# N32L406 register map
Vendor: Nsing Technologies Pte. Ltd.; File version: 1.0
Registers are 32-bit, read-write, reset 0x0 unless marked. A register's access mark holds for its fields unless they carry their own. Offsets are from the block's base; [hi:lo] are bit positions; {n}, {i} and the like mark numbered series; 'fields as' and 'values as' point back to an identical list.

## CRC — cyclic redundancy check
Base 0x40023000
0x00 CRC32DAT reset 0xFFFFFFFF
0x04 CRC32IDAT
  [7:0] CRC32IDAT
0x08 CRC32CTRL
  [0] RESET
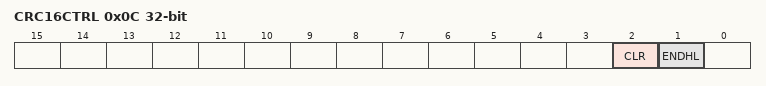
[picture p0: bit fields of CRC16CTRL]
0x0C CRC16CTRL
  [2] CLR, [1] ENDHL
0x10 CRC16DAT
  [7:0] CRC16DAT
0x14 CRC16D
  [15:0] CRC16D
0x18 LRC
  [7:0] LRCDAT

## DAC — digital to analog converter
Base 0x40007400
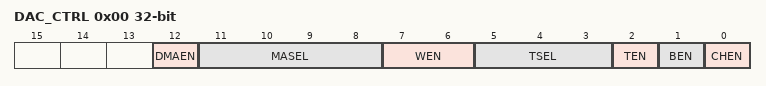
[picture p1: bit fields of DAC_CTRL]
0x00 DAC_CTRL
  [12] DMAEN, [11:8] MASEL, [7:6] WEN, [5:3] TSEL, [2] TEN, [1] BEN, [0] CHEN
0x04 DAC_SOTTR write
  [0] TR1EN
0x08 DAC_DR12CH
  [11:0] DACCHD
0x0C DAC_DL12CH
  [15:4] DACCHD
0x10 DAC_DR8CH
  [7:0] DACCHD
0x2C DAC_DATO
  [11:0] DACCHDO

## DBG — debug support for MCU
Base 0xE0042000
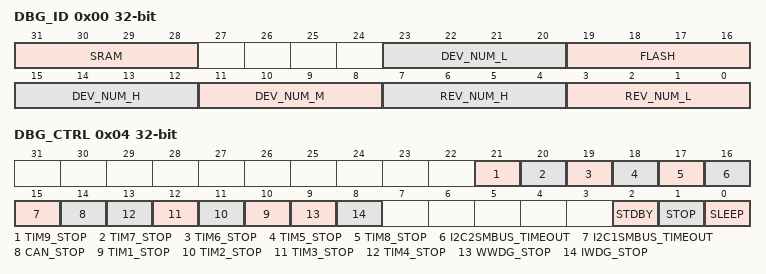
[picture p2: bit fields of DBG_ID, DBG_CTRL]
0x00 DBG_ID
  [31:28] SRAM, [23:20] DEV_NUM_L, [19:16] FLASH, [15:12] DEV_NUM_H, [11:8] DEV_NUM_M, [7:4] REV_NUM_H, [3:0] REV_NUM_L
0x04 DBG_CTRL
  [21] TIM9_STOP, [20] TIM7_STOP, [19] TIM6_STOP, [18] TIM5_STOP, [17] TIM8_STOP, [16] I2C2SMBUS_TIMEOUT, [15] I2C1SMBUS_TIMEOUT, [14] CAN_STOP, [n+9] TIM{n}_STOP (n=1..4), [9] WWDG_STOP, [8] IWDG_STOP, [2] STDBY, [1] STOP, [0] SLEEP

## DMA — Direct memory access controller
Base 0x40020000
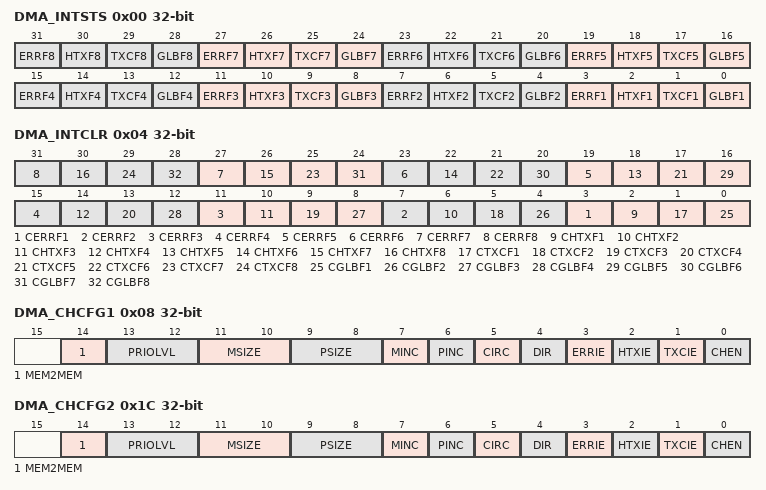
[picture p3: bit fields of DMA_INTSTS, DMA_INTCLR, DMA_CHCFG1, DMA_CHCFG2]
0x00 DMA_INTSTS
  [4n-1] ERRF{n} (n=1..8), [4n-2] HTXF{n} (n=1..8), [4n-3] TXCF{n} (n=1..8), [4n-4] GLBF{n} (n=1..8)
0x04 DMA_INTCLR
  [4n-1] CERRF{n} (n=1..8), [4n-2] CHTXF{n} (n=1..8), [4n-3] CTXCF{n} (n=1..8), [4n-4] CGLBF{n} (n=1..8)
0x08 DMA_CHCFG1
  [14] MEM2MEM, [13:12] PRIOLVL, [11:10] MSIZE, [9:8] PSIZE, [7] MINC, [6] PINC, [5] CIRC, [4] DIR, [3] ERRIE, [2] HTXIE, [1] TXCIE, [0] CHEN
0x0C DMA_TXNUM1
  [15:0] NDTX
0x10 DMA_PADDR1
  [31:0] ADDR
{0x0+0x14*i} DMA_MADDR{i} (i=1..8)
  [31:0] ADDR
{0x4+0x14*i} DMA_CHSEL{i} (i=1..8)
  [5:0] CH_SEL
0x1C DMA_CHCFG2
  fields as DMA_CHCFG1
0x20 DMA_TXNUM2
  [15:0] NDTX
0x24 DMA_PADDR2
  [31:0] ADDR
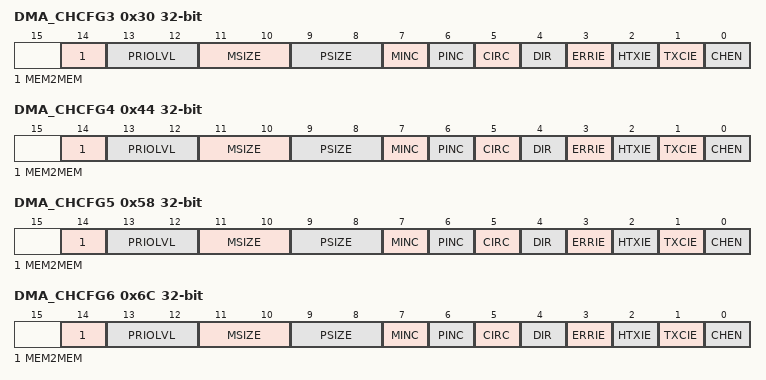
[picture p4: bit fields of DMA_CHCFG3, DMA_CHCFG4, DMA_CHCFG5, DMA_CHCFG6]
0x30 DMA_CHCFG3
  fields as DMA_CHCFG1
0x34 DMA_TXNUM3
  [15:0] NDTX
0x38 DMA_PADDR3
  [31:0] ADDR
0x44 DMA_CHCFG4
  fields as DMA_CHCFG1
0x48 DMA_TXNUM4
  [15:0] NDTX
0x4C DMA_PADDR4
  [31:0] ADDR
0x58 DMA_CHCFG5
  fields as DMA_CHCFG1
0x5C DMA_TXNUM5
  [15:0] NDTX
0x60 DMA_PADDR5
  [31:0] ADDR
0x6C DMA_CHCFG6
  fields as DMA_CHCFG1
0x70 DMA_TXNUM6
  [15:0] NDTX
0x74 DMA_PADDR6
  [31:0] ADDR
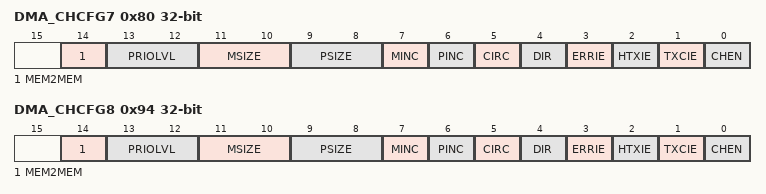
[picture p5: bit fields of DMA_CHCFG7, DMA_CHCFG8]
0x80 DMA_CHCFG7
  fields as DMA_CHCFG1
0x84 DMA_TXNUM7
  [15:0] NDTX
0x88 DMA_PADDR7
  [31:0] ADDR
0x94 DMA_CHCFG8
  fields as DMA_CHCFG1
0x98 DMA_TXNUM8
  [15:0] NDTX
0x9C DMA_PADDR8
  [31:0] ADDR

## EXTI — external interrupt/event controller
Base 0x40010400
0x00 EXTI_IMASK
  [27:0] IMASK
0x04 EXTI_EMASK
  [27:0] EMASK
0x08 EXTI_RT_CFG
  [27:0] RT_CFG
0x0C EXTI_FT_CFG
  [27:0] FT_CFG
0x10 EXTI_SWIE
  [27:0] SWIE
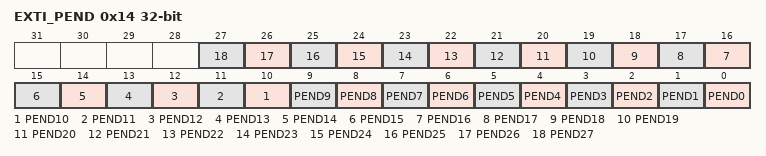
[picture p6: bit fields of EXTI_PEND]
0x14 EXTI_PEND
  [n] PEND{n} (n=0..27)
0x18 EXTI_TS_SEL
  [3:0] TSSEL

## FLASH — interal FLASH controller
Base 0x40022000
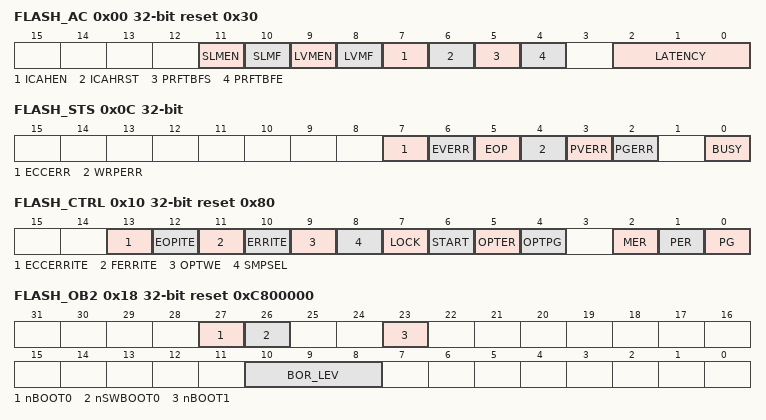
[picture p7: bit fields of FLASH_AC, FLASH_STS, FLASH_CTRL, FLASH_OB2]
0x00 FLASH_AC reset 0x30
  [11] SLMEN, [10] SLMF, [9] LVMEN, [8] LVMF, [7] ICAHEN, [6] ICAHRST, [5] PRFTBFS, [4] PRFTBFE, [2:0] LATENCY
0x04 FLASH_KEY
  [31:0] FKEY
0x08 FLASH_OPTKEY
0x0C FLASH_STS
  [7] ECCERR, [6] EVERR, [5] EOP, [4] WRPERR, [3] PVERR, [2] PGERR, [0] BUSY
0x10 FLASH_CTRL reset 0x80
  [13] ECCERRITE, [12] EOPITE, [11] FERRITE, [10] ERRITE, [9] OPTWE, [8] SMPSEL, [7] LOCK, [6] START, [5] OPTER, [4] OPTPG, [2] MER, [1] PER, [0] PG
0x14 FLASH_ADD
  [31:0] FADD
0x18 FLASH_OB2 reset 0xC800000
  [27] nBOOT0, [26] nSWBOOT0, [23] nBOOT1, [10:8] BOR_LEV
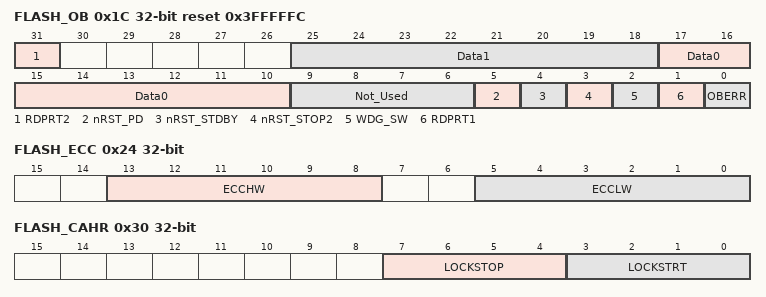
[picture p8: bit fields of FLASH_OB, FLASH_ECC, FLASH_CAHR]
0x1C FLASH_OB reset 0x3FFFFFC
  [31] RDPRT2, [25:18] Data1, [17:10] Data0, [9:6] Not_Used, [5] nRST_PD, [4] nRST_STDBY, [3] nRST_STOP2, [2] WDG_SW, [1] RDPRT1, [0] OBERR
0x20 FLASH_WRP reset 0xFFFFFFFF
  [31:0] WRPT
0x24 FLASH_ECC
  [13:8] ECCHW, [5:0] ECCLW
0x30 FLASH_CAHR
  [7:4] LOCKSTOP, [3:0] LOCKSTRT

## GPIOA — General purpose I/O
Base 0x40010800
Same registers: GPIOB 0x40010C00, GPIOC 0x40011000, GPIOD 0x40011400
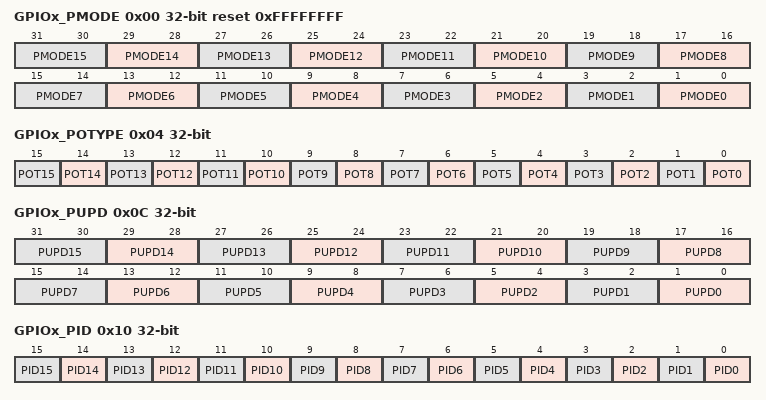
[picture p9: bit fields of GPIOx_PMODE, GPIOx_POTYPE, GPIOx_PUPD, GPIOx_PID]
0x00 GPIOx_PMODE reset 0xFFFFFFFF
  [2n+1:2n] PMODE{n} (n=0..15)
0x04 GPIOx_POTYPE
  [n] POT{n} (n=0..15)
0x0C GPIOx_PUPD
  [2n+1:2n] PUPD{n} (n=0..15)
0x10 GPIOx_PID
  [n] PID{n} (n=0..15)
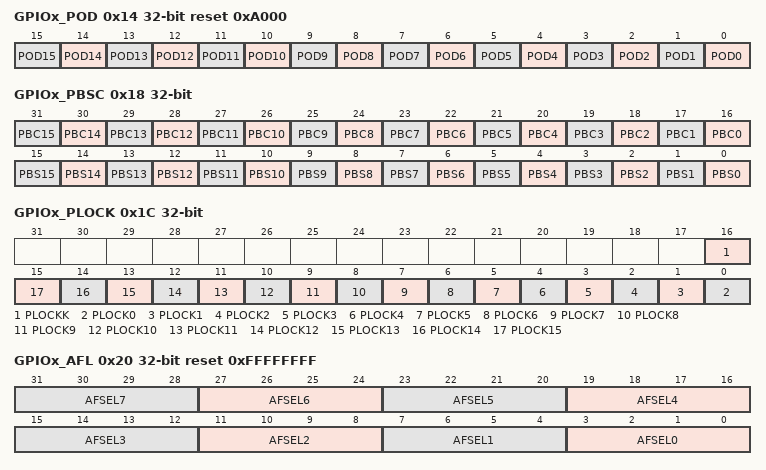
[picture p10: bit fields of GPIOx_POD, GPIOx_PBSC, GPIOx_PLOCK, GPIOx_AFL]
0x14 GPIOx_POD reset 0xA000
  [n] POD{n} (n=0..15)
0x18 GPIOx_PBSC
  [n+16] PBC{n} (n=0..15), [n] PBS{n} (n=0..15)
0x1C GPIOx_PLOCK
  [16] PLOCKK, [n] PLOCK{n} (n=0..15)
0x20 GPIOx_AFL reset 0xFFFFFFFF
  [4n+3:4n] AFSEL{n} (n=0..7)
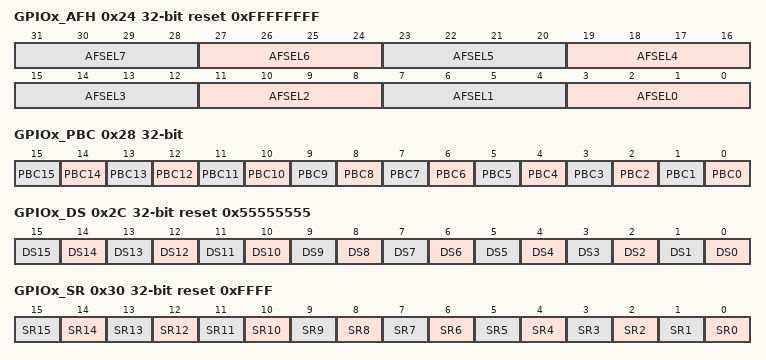
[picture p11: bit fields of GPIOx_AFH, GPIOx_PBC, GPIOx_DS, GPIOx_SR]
0x24 GPIOx_AFH reset 0xFFFFFFFF
  [4n+3:4n] AFSEL{n} (n=0..7)
0x28 GPIOx_PBC
  [n] PBC{n} (n=0..15)
0x2C GPIOx_DS reset 0x55555555
  [n] DS{n} (n=0..15)
0x30 GPIOx_SR reset 0xFFFF
  [n] SR{n} (n=0..15)
